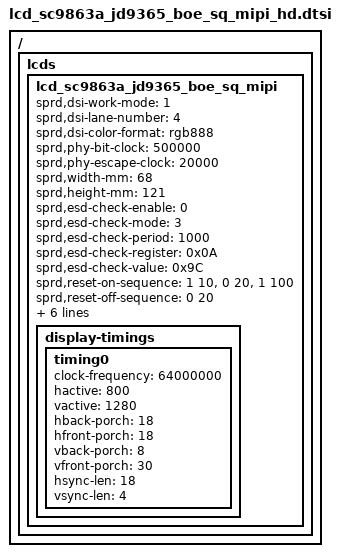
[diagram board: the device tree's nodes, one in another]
/ { lcds {
	lcd_sc9863a_jd9365_boe_sq_mipi: lcd_sc9863a_jd9365_boe_sq_mipi {

		sprd,dsi-work-mode = <1>;
		sprd,dsi-lane-number = <4>;
		sprd,dsi-color-format = "rgb888";

		sprd,phy-bit-clock = <500000>;
		sprd,phy-escape-clock = <20000>;

		sprd,width-mm = <68>;
		sprd,height-mm = <121>;

		sprd,esd-check-enable = <0>;
		sprd,esd-check-mode = <3>;
		sprd,esd-check-period = <1000>;
		sprd,esd-check-register = <0x0A>;
		sprd,esd-check-value = <0x9C>;

		sprd,reset-on-sequence = <1 10>, <0 20>, <1 100>;
		sprd,reset-off-sequence = <0 20>;

		sprd,initial-command = [
		
			23 00 00 02 E0 00
			23 00 00 02 E1 93
			23 00 00 02 E2 65
			23 00 00 02 E3 F8
			23 00 00 02 80 03

			//Lane select by internal reg  4 lanes
			23 00 00 02 E0 04
			23 00 00 02 2D 03//defult 0x01

			23 00 00 02 E0 00
			//--- Sequence Ctrl  ----//
			23 00 00 02 70 02	//DC0DC1
			23 00 00 02 71 23	//DC2DC3
			23 00 00 02 72 06	//DC7

			//--- Page1  ----//
			23 00 00 02 E0 01
			//Set VCOM
			23 00 00 02 00 00
			23 00 00 02 01 60    
			//Set VCOM_Reverse
			23 00 00 02 03 00
			23 00 00 02 04 60
			//Set Gamma Power VGMPVGMNVGSPVGSN
			23 00 00 02 17 00
			23 00 00 02 18 BF//4.5V
			23 00 00 02 19 00
			23 00 00 02 1A 00
			23 00 00 02 1B BF  //VGMN=-4.5V
			23 00 00 02 1C 00
						   
			//Set Gate Power
			23 00 00 02 1F 3E     //VGH_R  = 15V                       
			23 00 00 02 20 28     //VGL_R  = -11V                      
			23 00 00 02 21 28     //VGL_R2 = -11V                      
			23 00 00 02 22 0E     //PA[6]=0 PA[5]=0 PA[4]=0 PA[0]=0 

			//SETPANEL
			23 00 00 02 37 09	//SS=1BGR=1
			//SET RGBCYC
			23 00 00 02 38 04	//JDT=100 column inversion
			23 00 00 02 39 08	//RGB_N_EQ1 modify 20140806
			23 00 00 02 3A 12	//RGB_N_EQ2 modify 20140806
			23 00 00 02 3C 78	//SET EQ3 for TE_H
			23 00 00 02 3D FF	//SET CHGEN_ON modify 20140806 
			23 00 00 02 3E FF	//SET CHGEN_OFF modify 20140806 
			23 00 00 02 3F 7F	//SET CHGEN_OFF2 modify 20140806

			//Set TCON
			23 00 00 02 40 06	//RSO=800 RGB
			23 00 00 02 41 A0	//LN=640->1280 line
			//--- power voltage  ----//
			23 00 00 02 55 01	//DCDCM=0001 JD PWR_IC
			23 00 00 02 56 01
			23 00 00 02 57 69
			23 00 00 02 58 0A
			23 00 00 02 59 0A	//VCL = -2.5V
			23 00 00 02 5A 29	//VGH = 15.2V
			23 00 00 02 5B 15	//VGL = -11.2V

			//--- Gamma  ----//
			23 00 00 02 5D 7C              
			23 00 00 02 5E 65      
			23 00 00 02 5F 55    
			23 00 00 02 60 49    
			23 00 00 02 61 44    
			23 00 00 02 62 35    
			23 00 00 02 63 3A    
			23 00 00 02 64 23    
			23 00 00 02 65 3D    
			23 00 00 02 66 3C    
			23 00 00 02 67 3D    
			23 00 00 02 68 5D    
			23 00 00 02 69 4D    
			23 00 00 02 6A 56    
			23 00 00 02 6B 48    
			23 00 00 02 6C 45    
			23 00 00 02 6D 38    
			23 00 00 02 6E 25    
			23 00 00 02 6F 00    
			23 00 00 02 70 7C    
			23 00 00 02 71 65    
			23 00 00 02 72 55    
			23 00 00 02 73 49    
			23 00 00 02 74 44    
			23 00 00 02 75 35    
			23 00 00 02 76 3A    
			23 00 00 02 77 23    
			23 00 00 02 78 3D    
			23 00 00 02 79 3C    
			23 00 00 02 7A 3D    
			23 00 00 02 7B 5D    
			23 00 00 02 7C 4D    
			23 00 00 02 7D 56    
			23 00 00 02 7E 48    
			23 00 00 02 7F 45    
			23 00 00 02 80 38    
			23 00 00 02 81 25    
			23 00 00 02 82 00    
											 
			//Page2 for GIP                                      
			23 00 00 02 E0 02                                
			//GIP_L Pin mapping                                   
			23 00 00 02 00 1E//1  VDS                        
			23 00 00 02 01 1E//2  VDS                        
			23 00 00 02 02 41//3  STV2                       
			23 00 00 02 03 41//4  STV2                       
			23 00 00 02 04 43//5  STV4                       
			23 00 00 02 05 43//6  STV4                       
			23 00 00 02 06 1F//7  VSD                        
			23 00 00 02 07 1F//8  VSD                        
			23 00 00 02 08 1F//9  GCL                        
			23 00 00 02 09 1F//10                            
			23 00 00 02 0A 1E//11 GCH                        
			23 00 00 02 0B 1E//12 GCH                        
			23 00 00 02 0C 1F//13                            
			23 00 00 02 0D 47//14 CLK8                       
			23 00 00 02 0E 47//15 CLK8                       
			23 00 00 02 0F 45//16 CLK6                       
			23 00 00 02 10 45//17 CLK6                       
			23 00 00 02 11 4B//18 CLK4                       
			23 00 00 02 12 4B//19 CLK4                       
			23 00 00 02 13 49//20 CLK2                       
			23 00 00 02 14 49//21 CLK2                       
			23 00 00 02 15 1F//22 VGL                        
																  
																  
			//GIP_R Pin mapping                                   
			23 00 00 02 16 1E//1  VDS                 
			23 00 00 02 17 1E//2  VDS                
			23 00 00 02 18 40//3  STV1               
			23 00 00 02 19 40//4  STV1               
			23 00 00 02 1A 42//5  STV3               
			23 00 00 02 1B 42//6  STV3               
			23 00 00 02 1C 1F//7  VSD                
			23 00 00 02 1D 1F//8  VSD                
			23 00 00 02 1E 1F//9  GCL                
			23 00 00 02 1F 1f//10                    
			23 00 00 02 20 1E//11 GCH                
			23 00 00 02 21 1E//12 GCH                
			23 00 00 02 22 1f//13                    
			23 00 00 02 23 46//14 CLK7               
			23 00 00 02 24 46//15 CLK7               
			23 00 00 02 25 44//16 CLK5               
			23 00 00 02 26 44//17 CLK5               
			23 00 00 02 27 4A//18 CLK3               
			23 00 00 02 28 4A//19 CLK3               
			23 00 00 02 29 48//20 CLK1               
			23 00 00 02 2A 48//21 CLK1               
			23 00 00 02 2B 1f//22 VGL                                 
				 
			//GIP_L_GS Pin mapping
			23 00 00 02 2C 1F//1  VDS 		0x1E
			23 00 00 02 2D 1F//2  VDS          0x1E
			23 00 00 02 2E 42//3  STV2         0x41
			23 00 00 02 2F 42//4  STV2         0x41
			23 00 00 02 30 40//5  STV4         0x43
			23 00 00 02 31 40//6  STV4         0x43
			23 00 00 02 32 1E//7  VSD          0x1F
			23 00 00 02 33 1E//8  VSD          0x1F
			23 00 00 02 34 1F//9  GCL          0x1F
			23 00 00 02 35 1F//10              0x1F
			23 00 00 02 36 1E//11 GCH          0x1E
			23 00 00 02 37 1E//12 GCH          0x1E
			23 00 00 02 38 1F//13              0x1F
			23 00 00 02 39 48//14 CLK8         0x47
			23 00 00 02 3A 48//15 CLK8         0x47
			23 00 00 02 3B 4A//16 CLK6         0x45
			23 00 00 02 3C 4A//17 CLK6         0x45
			23 00 00 02 3D 44//18 CLK4         0x4B
			23 00 00 02 3E 44//19 CLK4         0x4B
			23 00 00 02 3F 46//20 CLK2         0x49
			23 00 00 02 40 46//21 CLK2         0x49
			23 00 00 02 41 1F//22 VGL          0x1F

			//GIP_R_GS Pin mapping
			23 00 00 02 42 1F//1  VDS 		0x1E
			23 00 00 02 43 1F//2  VDS          0x1E
			23 00 00 02 44 43//3  STV1         0x40
			23 00 00 02 45 43//4  STV1         0x40
			23 00 00 02 46 41//5  STV3         0x42
			23 00 00 02 47 41//6  STV3         0x42
			23 00 00 02 48 1E//7  VSD          0x1F
			23 00 00 02 49 1E//8  VSD          0x1F
			23 00 00 02 4A 1E//9  GCL          0x1F
			23 00 00 02 4B 1F//10              0x1f
			23 00 00 02 4C 1E//11 GCH          0x1E
			23 00 00 02 4D 1E//12 GCH          0x1E
			23 00 00 02 4E 1F//13              0x1f
			23 00 00 02 4F 49//14 CLK7         0x46
			23 00 00 02 50 49//15 CLK7         0x46
			23 00 00 02 51 4B//16 CLK5         0x44
			23 00 00 02 52 4B//17 CLK5         0x44
			23 00 00 02 53 45//18 CLK3         0x4A
			23 00 00 02 54 45//19 CLK3         0x4A
			23 00 00 02 55 47//20 CLK1         0x48
			23 00 00 02 56 47//21 CLK1         0x48
			23 00 00 02 57 1F//22 VGL          0x1f

			//GIP Timing  
			23 00 00 02 58 10 
			23 00 00 02 59 00 
			23 00 00 02 5A 00 
			23 00 00 02 5B 30 //STV_S0
			23 00 00 02 5C 02 //STV_S0
			23 00 00 02 5D 40 //STV_W / S1
			23 00 00 02 5E 01 //STV_S2
			23 00 00 02 5F 02 //STV_S3
			23 00 00 02 60 30 //ETV_W / S1
			23 00 00 02 61 01 //ETV_S2
			23 00 00 02 62 02 //ETV_S3
			23 00 00 02 63 6A //SETV_ON  
			23 00 00 02 64 6A //SETV_OFF 
			23 00 00 02 65 05 //ETV
			23 00 00 02 66 12 
			23 00 00 02 67 74 
			23 00 00 02 68 04 
			23 00 00 02 69 6A 
			23 00 00 02 6A 6A 
			23 00 00 02 6B 08 
			23 00 00 02 6C 00 
			23 00 00 02 6D 04 
			23 00 00 02 6E 04 
			23 00 00 02 6F 88 
			23 00 00 02 70 00 
			23 00 00 02 71 00 
			23 00 00 02 72 06 
			23 00 00 02 73 7B 
			23 00 00 02 74 00 
			23 00 00 02 75 07 
			23 00 00 02 76 00 
			23 00 00 02 77 5D 
			23 00 00 02 78 17 
			23 00 00 02 79 1F 
			23 00 00 02 7A 00 
			23 00 00 02 7B 00 
			23 00 00 02 7C 00 
			23 00 00 02 7D 03 
			23 00 00 02 7E 7B 

			//Page4
			23 00 00 02 E0 04
			23 00 00 02 09 10
			23 00 00 02 2B 2B
			23 00 00 02 2E 44


			//Page0
			23 00 00 02 E0 00
			23 00 00 02 E6 02
			23 00 00 02 E7 02
			23 00 00 02 35 00 
			13 78 00 01 11
			13 64 00 01 29
			];
		sprd,sleep-in-command = [
			13 0A 00 01 28
			13 78 00 01 10
			];
		sprd,sleep-out-command = [
			13 78 00 01 11
			13 64 00 01 29
			];

		display-timings {
			timing0 {
			clock-frequency = <64000000>;
			hactive = <800>;
			vactive = <1280>;
			hback-porch = <18>;
			hfront-porch = <18>;
			vback-porch = <8>;
			vfront-porch = <30>;
			hsync-len = <18>;
			vsync-len = <4>;
			};
		};
	};
};};

